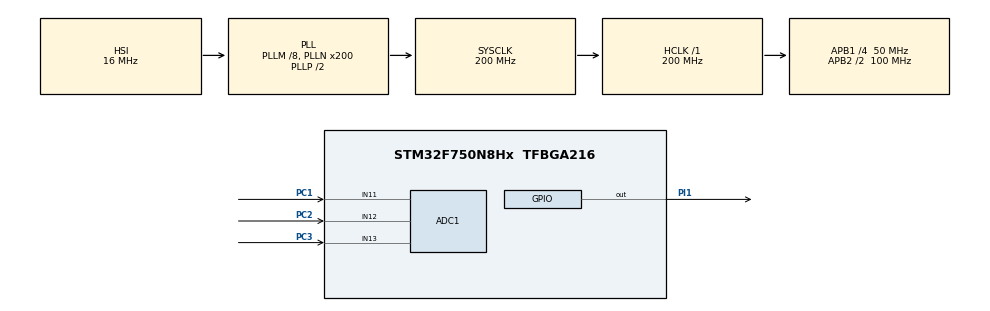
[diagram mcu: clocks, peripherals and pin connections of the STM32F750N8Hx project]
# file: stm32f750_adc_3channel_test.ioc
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ADC1.Channel-0\#ChannelRegularConversion=ADC_CHANNEL_11
ADC1.Channel-1\#ChannelRegularConversion=ADC_CHANNEL_12
ADC1.Channel-3\#ChannelRegularConversion=ADC_CHANNEL_13
ADC1.ClockPrescaler=ADC_CLOCK_SYNC_PCLK_DIV8
ADC1.EOCSelection=ADC_EOC_SEQ_CONV
ADC1.NbrOfConversion=3
ADC1.NbrOfConversionFlag=1
ADC1.Rank-0\#ChannelRegularConversion=1
ADC1.Rank-1\#ChannelRegularConversion=2
ADC1.Rank-3\#ChannelRegularConversion=3
ADC1.SamplingTime-0\#ChannelRegularConversion=ADC_SAMPLETIME_56CYCLES
ADC1.SamplingTime-1\#ChannelRegularConversion=ADC_SAMPLETIME_56CYCLES
ADC1.SamplingTime-3\#ChannelRegularConversion=ADC_SAMPLETIME_56CYCLES
ADC1.ScanConvMode=ADC_SCAN_ENABLE
ADC1.master=1
Dma.ADC1.0.Direction=DMA_PERIPH_TO_MEMORY
Dma.ADC1.0.FIFOMode=DMA_FIFOMODE_DISABLE
Dma.ADC1.0.Instance=DMA2_Stream0
Dma.ADC1.0.MemDataAlignment=DMA_MDATAALIGN_HALFWORD
Dma.ADC1.0.MemInc=DMA_MINC_ENABLE
Dma.ADC1.0.Mode=DMA_CIRCULAR
Dma.ADC1.0.PeriphDataAlignment=DMA_PDATAALIGN_HALFWORD
Dma.ADC1.0.PeriphInc=DMA_PINC_DISABLE
Dma.ADC1.0.Priority=DMA_PRIORITY_LOW
Dma.Request0=ADC1
Mcu.Family=STM32F7
Mcu.Name=STM32F750N8Hx
Mcu.Package=TFBGA216
NVIC.DMA2_Stream0_IRQn=true\:0\:0\:true\:false\:true\:false\:true
NVIC.PriorityGroup=NVIC_PRIORITYGROUP_4
PA13.Mode=Serial_Wire
PA13.Signal=SYS_JTMS-SWDIO
PA14.Mode=Serial_Wire
PA14.Signal=SYS_JTCK-SWCLK
PC1.GPIO_Mode=GPIO_MODE_ANALOG
PC1.Signal=ADCx_IN11
PC2.GPIO_Mode=GPIO_MODE_ANALOG
PC2.Signal=ADCx_IN12
PC3.GPIO_Mode=GPIO_MODE_ANALOG
PC3.Signal=ADCx_IN13
PI1.Signal=GPIO_Output
ProjectManager.HeapSize=0x200
ProjectManager.StackSize=0x400
ProjectManager.TargetToolchain=TrueSTUDIO
RCC.AHBFreq_Value=200000000
RCC.APB1CLKDivider=RCC_HCLK_DIV4
RCC.APB1Freq_Value=50000000
RCC.APB1TimFreq_Value=100000000
RCC.APB2CLKDivider=RCC_HCLK_DIV2
RCC.APB2Freq_Value=100000000
RCC.APB2TimFreq_Value=200000000
RCC.CortexFreq_Value=200000000
RCC.HCLKFreq_Value=200000000
RCC.HSE_VALUE=25000000
RCC.HSI_VALUE=16000000
RCC.LSE_VALUE=32768
RCC.PLLM=8
RCC.PLLN=200
RCC.SYSCLKFreq_VALUE=200000000
RCC.SYSCLKSource=RCC_SYSCLKSOURCE_PLLCLK
RCC.USBFreq_Value=200000000
RCC.VCOOutputFreq_Value=400000000
SH.ADCx_IN11.0=ADC1_IN11,IN11
SH.ADCx_IN12.0=ADC1_IN12,IN12
SH.ADCx_IN13.0=ADC1_IN13,IN13
board=custom

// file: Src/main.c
/* USER CODE BEGIN Header */
/**
  ******************************************************************************
  * @file           : main.c
  * @brief          : Main program body
  ******************************************************************************
  * @attention
  *
  * <h2><center>&copy; Copyright (c) 2020 STMicroelectronics.
  * All rights reserved.</center></h2>
  *
  * This software component is licensed by ST under BSD 3-Clause license,
  * the "License"; You may not use this file except in compliance with the
  * License. You may obtain a copy of the License at:
  *                        opensource.org/licenses/BSD-3-Clause
  *
  ******************************************************************************
  */
/* USER CODE END Header */

#include "main.h"
#include "adc.h"
#include "dma.h"
#include "gpio.h"

void SystemClock_Config(void);

/* USER CODE BEGIN 0 */
__IO uint16_t uhADCxConvertedValue[3]={0};
/* USER CODE END 0 */

int main(void)
{

  /* MCU Configuration--------------------------------------------------------*/

  /* Reset of all peripherals, Initializes the Flash interface and the Systick. */
  HAL_Init();

  /* Configure the system clock */
  SystemClock_Config();

  /* Initialize all configured peripherals */
  MX_GPIO_Init();
  MX_DMA_Init();
  MX_ADC1_Init();

  /* Infinite loop */
  /* USER CODE BEGIN WHILE */

  while (1)
  {
    if(HAL_ADC_Start_DMA(&hadc1, (uint32_t*)&uhADCxConvertedValue, 3) != HAL_OK)
    {
      /* Start Conversation Error */
      Error_Handler();
    }

    HAL_Delay(100);
    /* USER CODE END WHILE */

  }
}

void SystemClock_Config(void)
{
  RCC_OscInitTypeDef RCC_OscInitStruct = {0};
  RCC_ClkInitTypeDef RCC_ClkInitStruct = {0};

  /** Configure the main internal regulator output voltage
  */
  __HAL_RCC_PWR_CLK_ENABLE();
  __HAL_PWR_VOLTAGESCALING_CONFIG(PWR_REGULATOR_VOLTAGE_SCALE1);
  /** Initializes the CPU, AHB and APB busses clocks
  */
  RCC_OscInitStruct.OscillatorType = RCC_OSCILLATORTYPE_HSI;
  RCC_OscInitStruct.HSIState = RCC_HSI_ON;
  RCC_OscInitStruct.HSICalibrationValue = RCC_HSICALIBRATION_DEFAULT;
  RCC_OscInitStruct.PLL.PLLState = RCC_PLL_ON;
  RCC_OscInitStruct.PLL.PLLSource = RCC_PLLSOURCE_HSI;
  RCC_OscInitStruct.PLL.PLLM = 8;
  RCC_OscInitStruct.PLL.PLLN = 200;
  RCC_OscInitStruct.PLL.PLLP = RCC_PLLP_DIV2;
  RCC_OscInitStruct.PLL.PLLQ = 2;
  if (HAL_RCC_OscConfig(&RCC_OscInitStruct) != HAL_OK)
  {
    Error_Handler();
  }
  /** Activate the Over-Drive mode
  */
  if (HAL_PWREx_EnableOverDrive() != HAL_OK)
  {
    Error_Handler();
  }
  /** Initializes the CPU, AHB and APB busses clocks
  */
  RCC_ClkInitStruct.ClockType = RCC_CLOCKTYPE_HCLK|RCC_CLOCKTYPE_SYSCLK
                              |RCC_CLOCKTYPE_PCLK1|RCC_CLOCKTYPE_PCLK2;
  RCC_ClkInitStruct.SYSCLKSource = RCC_SYSCLKSOURCE_PLLCLK;
  RCC_ClkInitStruct.AHBCLKDivider = RCC_SYSCLK_DIV1;
  RCC_ClkInitStruct.APB1CLKDivider = RCC_HCLK_DIV4;
  RCC_ClkInitStruct.APB2CLKDivider = RCC_HCLK_DIV2;

  if (HAL_RCC_ClockConfig(&RCC_ClkInitStruct, FLASH_LATENCY_6) != HAL_OK)
  {
    Error_Handler();
  }
}

/* USER CODE BEGIN 4 */
void HAL_ADC_ConvCpltCallback(ADC_HandleTypeDef* hadc)
{
  HAL_GPIO_TogglePin(GPIOI, GPIO_PIN_1);
  HAL_ADC_Stop_DMA(&hadc1);
}
/* USER CODE END 4 */

void Error_Handler(void)
{
  /* USER CODE BEGIN Error_Handler_Debug */
  /* User can add his own implementation to report the HAL error return state */
  while(1);
  /* USER CODE END Error_Handler_Debug */
}

/************************ (C) COPYRIGHT STMicroelectronics *****END OF FILE****/
